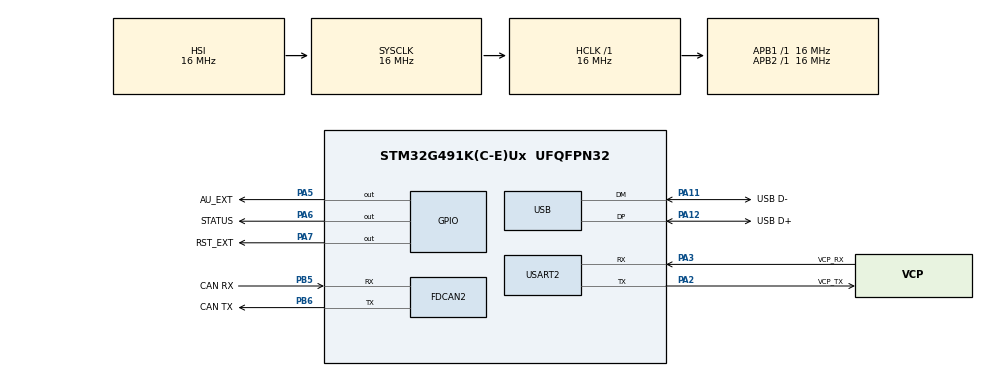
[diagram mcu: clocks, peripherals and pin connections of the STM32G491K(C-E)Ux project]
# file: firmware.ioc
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FDCAN2.CalculateBaudRateNominal=200000
FDCAN2.CalculateTimeBitNominal=5000
FDCAN2.CalculateTimeQuantumNominal=1000.0
Mcu.Family=STM32G4
Mcu.Name=STM32G491K(C-E)Ux
Mcu.Package=UFQFPN32
NVIC.PriorityGroup=NVIC_PRIORITYGROUP_4
PA11.GPIO_Label=USB D-
PA11.Mode=Device
PA11.Signal=USB_DM
PA12.GPIO_Label=USB D+
PA12.Mode=Device
PA12.Signal=USB_DP
PA13.GPIO_Label=SWDIO
PA13.Mode=Trace_Asynchronous_SW
PA13.Signal=SYS_JTMS-SWDIO
PA14.GPIO_Label=SWCLK 
PA14.Mode=Trace_Asynchronous_SW
PA14.Signal=SYS_JTCK-SWCLK
PA2.GPIO_Label=VCP_TX
PA2.Mode=Asynchronous
PA2.Signal=USART2_TX
PA3.GPIO_Label=VCP_RX
PA3.Mode=Asynchronous
PA3.Signal=USART2_RX
PA5.GPIO_Label=AU_EXT
PA5.Signal=GPIO_Output
PA6.GPIO_Label=STATUS
PA6.Signal=GPIO_Output
PA7.GPIO_Label=RST_EXT
PA7.Signal=GPIO_Output
PB3.GPIO_Label=SWO
PB3.Mode=Trace_Asynchronous_SW
PB3.Signal=SYS_JTDO-SWO
PB5.GPIO_Label=CAN RX 
PB5.Mode=FDCAN_Activate
PB5.Signal=FDCAN2_RX
PB6.GPIO_Label=CAN TX
PB6.Mode=FDCAN_Activate
PB6.Signal=FDCAN2_TX
ProjectManager.HeapSize=0x200
ProjectManager.StackSize=0x400
ProjectManager.TargetToolchain=STM32CubeIDE
RCC.AHBFreq_Value=16000000
RCC.APB1Freq_Value=16000000
RCC.APB1TimFreq_Value=16000000
RCC.APB2Freq_Value=16000000
RCC.APB2TimFreq_Value=16000000
RCC.CortexFreq_Value=16000000
RCC.EXTERNAL_CLOCK_VALUE=12288000
RCC.HCLKFreq_Value=16000000
RCC.HSE_VALUE=8000000
RCC.HSI48_VALUE=48000000
RCC.HSI_VALUE=16000000
RCC.LSE_VALUE=32768
RCC.SYSCLKFreq_VALUE=16000000
RCC.USBFreq_Value=48000000
RCC.VCOOutputFreq_Value=128000000
USART2.VirtualMode-Asynchronous=VM_ASYNC
VP_SYS_VS_DBSignals.Mode=DisableDeadBatterySignals
board=custom

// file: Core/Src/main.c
/* USER CODE BEGIN Header */
/**
  ******************************************************************************
  * @file           : main.c
  * @brief          : Main program body
  ******************************************************************************
  * @attention
  *
  * Copyright (c) 2024 STMicroelectronics.
  * All rights reserved.
  *
  * This software is licensed under terms that can be found in the LICENSE file
  * in the root directory of this software component.
  * If no LICENSE file comes with this software, it is provided AS-IS.
  *
  ******************************************************************************
  */
/* USER CODE END Header */
#include "main.h"

/* USER CODE BEGIN Includes */
#include "Utils/global.h"
#include "Utils/mainloop.h"
/* USER CODE END Includes */

FDCAN_HandleTypeDef hfdcan2;

UART_HandleTypeDef huart2;

PCD_HandleTypeDef hpcd_USB_FS;

void SystemClock_Config(void);
static void MX_GPIO_Init(void);
static void MX_FDCAN2_Init(void);
static void MX_USART2_UART_Init(void);
static void MX_USB_PCD_Init(void);

int main(void)
{

  /* MCU Configuration--------------------------------------------------------*/

  /* Reset of all peripherals, Initializes the Flash interface and the Systick. */
  HAL_Init();

  /* Configure the system clock */
  SystemClock_Config();

  /* Initialize all configured peripherals */
  MX_GPIO_Init();
  MX_FDCAN2_Init();
  MX_USART2_UART_Init();
  MX_USB_PCD_Init();
  /* USER CODE BEGIN 2 */
  main_init(&hfdcan2, &hpcd_USB_FS);
  /* USER CODE END 2 */

  /* Infinite loop */
  while (1)
  {
	  mainloop(&hfdcan2, &hpcd_USB_FS);
  }
}

void SystemClock_Config(void)
{
  RCC_OscInitTypeDef RCC_OscInitStruct = {0};
  RCC_ClkInitTypeDef RCC_ClkInitStruct = {0};

  /** Configure the main internal regulator output voltage
  */
  HAL_PWREx_ControlVoltageScaling(PWR_REGULATOR_VOLTAGE_SCALE1);

  /** Initializes the RCC Oscillators according to the specified parameters
  * in the RCC_OscInitTypeDef structure.
  */
  RCC_OscInitStruct.OscillatorType = RCC_OSCILLATORTYPE_HSI|RCC_OSCILLATORTYPE_HSI48;
  RCC_OscInitStruct.HSIState = RCC_HSI_ON;
  RCC_OscInitStruct.HSICalibrationValue = RCC_HSICALIBRATION_DEFAULT;
  RCC_OscInitStruct.HSI48State = RCC_HSI48_ON;
  RCC_OscInitStruct.PLL.PLLState = RCC_PLL_NONE;
  if (HAL_RCC_OscConfig(&RCC_OscInitStruct) != HAL_OK)
  {
    Error_Handler();
  }

  /** Initializes the CPU, AHB and APB buses clocks
  */
  RCC_ClkInitStruct.ClockType = RCC_CLOCKTYPE_HCLK|RCC_CLOCKTYPE_SYSCLK
                              |RCC_CLOCKTYPE_PCLK1|RCC_CLOCKTYPE_PCLK2;
  RCC_ClkInitStruct.SYSCLKSource = RCC_SYSCLKSOURCE_HSI;
  RCC_ClkInitStruct.AHBCLKDivider = RCC_SYSCLK_DIV1;
  RCC_ClkInitStruct.APB1CLKDivider = RCC_HCLK_DIV1;
  RCC_ClkInitStruct.APB2CLKDivider = RCC_HCLK_DIV1;

  if (HAL_RCC_ClockConfig(&RCC_ClkInitStruct, FLASH_LATENCY_0) != HAL_OK)
  {
    Error_Handler();
  }
}

static void MX_FDCAN2_Init(void)
{

  hfdcan2.Instance = FDCAN2;
  hfdcan2.Init.ClockDivider = FDCAN_CLOCK_DIV1;
  hfdcan2.Init.FrameFormat = FDCAN_FRAME_CLASSIC;
  hfdcan2.Init.Mode = FDCAN_MODE_NORMAL;
  hfdcan2.Init.AutoRetransmission = DISABLE;
  hfdcan2.Init.TransmitPause = DISABLE;
  hfdcan2.Init.ProtocolException = DISABLE;
  hfdcan2.Init.NominalPrescaler = 16;
  hfdcan2.Init.NominalSyncJumpWidth = 1;
  hfdcan2.Init.NominalTimeSeg1 = 2;
  hfdcan2.Init.NominalTimeSeg2 = 2;
  hfdcan2.Init.DataPrescaler = 1;
  hfdcan2.Init.DataSyncJumpWidth = 1;
  hfdcan2.Init.DataTimeSeg1 = 1;
  hfdcan2.Init.DataTimeSeg2 = 1;
  hfdcan2.Init.StdFiltersNbr = 0;
  hfdcan2.Init.ExtFiltersNbr = 0;
  hfdcan2.Init.TxFifoQueueMode = FDCAN_TX_FIFO_OPERATION;
  if (HAL_FDCAN_Init(&hfdcan2) != HAL_OK)
  {
    Error_Handler();
  }

}

static void MX_USART2_UART_Init(void)
{

  huart2.Instance = USART2;
  huart2.Init.BaudRate = 115200;
  huart2.Init.WordLength = UART_WORDLENGTH_8B;
  huart2.Init.StopBits = UART_STOPBITS_1;
  huart2.Init.Parity = UART_PARITY_NONE;
  huart2.Init.Mode = UART_MODE_TX_RX;
  huart2.Init.HwFlowCtl = UART_HWCONTROL_NONE;
  huart2.Init.OverSampling = UART_OVERSAMPLING_16;
  huart2.Init.OneBitSampling = UART_ONE_BIT_SAMPLE_DISABLE;
  huart2.Init.ClockPrescaler = UART_PRESCALER_DIV1;
  huart2.AdvancedInit.AdvFeatureInit = UART_ADVFEATURE_NO_INIT;
  if (HAL_UART_Init(&huart2) != HAL_OK)
  {
    Error_Handler();
  }
  if (HAL_UARTEx_SetTxFifoThreshold(&huart2, UART_TXFIFO_THRESHOLD_1_8) != HAL_OK)
  {
    Error_Handler();
  }
  if (HAL_UARTEx_SetRxFifoThreshold(&huart2, UART_RXFIFO_THRESHOLD_1_8) != HAL_OK)
  {
    Error_Handler();
  }
  if (HAL_UARTEx_DisableFifoMode(&huart2) != HAL_OK)
  {
    Error_Handler();
  }

}

static void MX_USB_PCD_Init(void)
{

  hpcd_USB_FS.Instance = USB;
  hpcd_USB_FS.Init.dev_endpoints = 8;
  hpcd_USB_FS.Init.speed = PCD_SPEED_FULL;
  hpcd_USB_FS.Init.phy_itface = PCD_PHY_EMBEDDED;
  hpcd_USB_FS.Init.Sof_enable = DISABLE;
  hpcd_USB_FS.Init.low_power_enable = DISABLE;
  hpcd_USB_FS.Init.lpm_enable = DISABLE;
  hpcd_USB_FS.Init.battery_charging_enable = DISABLE;
  if (HAL_PCD_Init(&hpcd_USB_FS) != HAL_OK)
  {
    Error_Handler();
  }

}

static void MX_GPIO_Init(void)
{
  GPIO_InitTypeDef GPIO_InitStruct = {0};

  /* GPIO Ports Clock Enable */
  __HAL_RCC_GPIOA_CLK_ENABLE();
  __HAL_RCC_GPIOB_CLK_ENABLE();

  /*Configure GPIO pin Output Level */
  HAL_GPIO_WritePin(GPIOA, AU_EXT_Pin|STATUS_Pin|RST_EXT_Pin, GPIO_PIN_RESET);

  /*Configure GPIO pins : AU_EXT_Pin STATUS_Pin RST_EXT_Pin */
  GPIO_InitStruct.Pin = AU_EXT_Pin|STATUS_Pin|RST_EXT_Pin;
  GPIO_InitStruct.Mode = GPIO_MODE_OUTPUT_PP;
  GPIO_InitStruct.Pull = GPIO_NOPULL;
  GPIO_InitStruct.Speed = GPIO_SPEED_FREQ_LOW;
  HAL_GPIO_Init(GPIOA, &GPIO_InitStruct);

}

void Error_Handler(void)
{
  __disable_irq();
  while (1)
  {
  }
}
